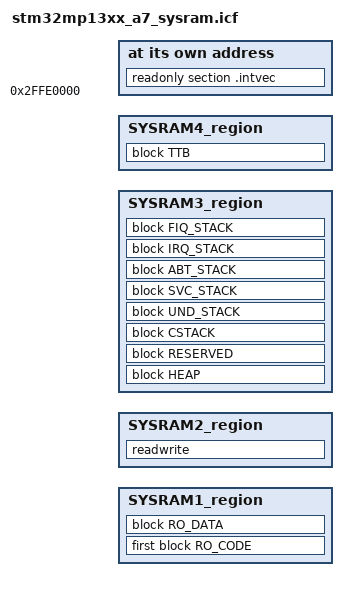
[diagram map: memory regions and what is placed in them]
/*###ICF### Section handled by ICF editor, don't touch! ****/
/*-Editor annotation file-*/
/* IcfEditorFile="$TOOLKIT_DIR$\config\ide\IcfEditor\a_v1_1.xml" */
/*-Specials-*/
define symbol __ICFEDIT_intvec_start__ = 0x2FFE0000;
/*-Memory Regions-*/
define symbol __ICFEDIT_region_SYSRAM1_BASE_start__ = 0x2FFE0000;
define symbol __ICFEDIT_region_SYSRAM1_BASE_end__   = 0x2FFEFFFF;
define symbol __ICFEDIT_region_SYSRAM2_BASE_start__ = 0x2FFF0000;
define symbol __ICFEDIT_region_SYSRAM2_BASE_end__   = 0x2FFF2FFF;
define symbol __ICFEDIT_region_SYSRAM3_BASE_start__ = 0x2FFF3000;
define symbol __ICFEDIT_region_SYSRAM3_BASE_end__   = 0x2FFF7FFF;
define symbol __ICFEDIT_region_SYSRAM4_BASE_start__ = 0x2FFF8000;
define symbol __ICFEDIT_region_SYSRAM4_BASE_end__   = 0x2FFFFFFF;
define symbol __ICFEDIT_region_SRAM1_BASE_start__     = 0x30000000;
define symbol __ICFEDIT_region_SRAM1_BASE_end__        = 0x30003FFF;
define symbol __ICFEDIT_region_SRAM2_BASE_start__      = 0x30004000;
define symbol __ICFEDIT_region_SRAM2_BASE_end__        = 0x30005FFF;
define symbol __ICFEDIT_region_SRAM3_BASE_start__      = 0x30006000;
define symbol __ICFEDIT_region_SRAM3_BASE_end__        = 0x30007FFF;
define symbol __ICFEDIT_region_DDR_BASE_start__  = 0xC0000000;
define symbol __ICFEDIT_region_DDR_BASE_end__    = 0xDF3FFFFF;
/*-Sizes-*/
define symbol __ICFEDIT_size_cstack__   = 0x1000;
define symbol __ICFEDIT_size_svcstack__ = 0x400;
define symbol __ICFEDIT_size_irqstack__ = 0x400;
define symbol __ICFEDIT_size_fiqstack__ = 0x400;
define symbol __ICFEDIT_size_undstack__ = 0x400;
define symbol __ICFEDIT_size_abtstack__ = 0x400;
define symbol __ICFEDIT_size_heap__     = 0x400;
define symbol __ICFEDIT_size_TTB_L1_SIZE__ = 16384;
define symbol __ICFEDIT_size_TTB_L2_SIZE__ = 1024;
define symbol __ICFEDIT_size_RESERVED_SIZE__ = 1024;
/**** End of ICF editor section. ###ICF###*/

define memory mem with size = 4G;
define symbol use_SYSRAM1 = (__ICFEDIT_region_SYSRAM1_BASE_start__ != 0x0 || __ICFEDIT_region_SYSRAM1_BASE_end__ != 0x0);
define symbol use_SYSRAM2 = (__ICFEDIT_region_SYSRAM2_BASE_start__ != 0x0 || __ICFEDIT_region_SYSRAM2_BASE_end__ != 0x0);
define symbol use_SYSRAM3 = (__ICFEDIT_region_SYSRAM3_BASE_start__ != 0x0 || __ICFEDIT_region_SYSRAM3_BASE_end__ != 0x0);
define symbol use_SYSRAM4 = (__ICFEDIT_region_SYSRAM4_BASE_start__ != 0x0 || __ICFEDIT_region_SYSRAM4_BASE_end__ != 0x0);
define symbol use_SRAM1 = (__ICFEDIT_region_SRAM1_BASE_start__ != 0x0 || __ICFEDIT_region_SRAM1_BASE_end__ != 0x0);
define symbol use_SRAM2 = (__ICFEDIT_region_SRAM2_BASE_start__ != 0x0 || __ICFEDIT_region_SRAM2_BASE_end__ != 0x0);
define symbol use_SRAM3 = (__ICFEDIT_region_SRAM3_BASE_start__ != 0x0 || __ICFEDIT_region_SRAM3_BASE_end__ != 0x0);
define symbol use_DDR = (__ICFEDIT_region_DDR_BASE_start__ != 0x0 || __ICFEDIT_region_DDR_BASE_end__ != 0x0);


if (use_SYSRAM1)
{
  define region SYSRAM1_region = mem:[from __ICFEDIT_region_SYSRAM1_BASE_start__ to __ICFEDIT_region_SYSRAM1_BASE_end__];
}
else
{
  define region SYSRAM1_region = [];
}
if (use_SYSRAM2)
{
  define region SYSRAM2_region = mem:[from __ICFEDIT_region_SYSRAM2_BASE_start__ to __ICFEDIT_region_SYSRAM2_BASE_end__];
}
else
{
  define region SYSRAM2_region = [];
}
if (use_SYSRAM3)
{
  define region SYSRAM3_region = mem:[from __ICFEDIT_region_SYSRAM3_BASE_start__ to __ICFEDIT_region_SYSRAM3_BASE_end__];
}
else
{
  define region SYSRAM3_region = [];
}

if (use_SYSRAM4)
{
  define region SYSRAM4_region = mem:[from __ICFEDIT_region_SYSRAM4_BASE_start__ to __ICFEDIT_region_SYSRAM4_BASE_end__];
}
else
{
  define region SYSRAM4_region = [];
}

/* define region SYSRAM_region = SYSRAM1_region | SYSRAM2_region | SYSRAM3_region; */


if (use_DDR)
{
  define region DDR_region = mem:[from __ICFEDIT_region_DDR_BASE_start__ to __ICFEDIT_region_DDR_BASE_end__];
}
else
{
  define region DDR_region = [];
}


initialize by copy { readwrite };
if (isdefinedsymbol(__USE_DLIB_PERTHREAD))
{
  /* Required in a multi-threaded application */
  initialize by copy with packing = none { section __DLIB_PERTHREAD };
}

place at address mem:__ICFEDIT_intvec_start__ { readonly section .intvec };

/*
* RO DATA 4k Alignment done as TTB pages are 4k Aligned. This avoids Prefetch Abort Error.
*/ 
if (!isempty(SYSRAM1_region))
{
  define block RO_CODE { ro code };
  define block RO_DATA with alignment = 4K { ro data };
  place in SYSRAM1_region  { first block RO_CODE, block RO_DATA };
}

if (!isempty(SYSRAM2_region))
{
  place in SYSRAM2_region  { readwrite };
}

/*if (!isempty(EROM_region))
{
  place in EROM_region  { readonly section application_specific_ro };
}
*/

if (!isempty(SYSRAM3_region))
{
  define block HEAP   with alignment = 8, size = __ICFEDIT_size_heap__   { };
  define block RESERVED with alignment = 8, size = __ICFEDIT_size_RESERVED_SIZE__  { };
  define block CSTACK    with alignment = 8, size = __ICFEDIT_size_cstack__   { };
  define block SVC_STACK with alignment = 8, size = __ICFEDIT_size_svcstack__ { };
  define block IRQ_STACK with alignment = 8, size = __ICFEDIT_size_irqstack__ { };
  define block FIQ_STACK with alignment = 8, size = __ICFEDIT_size_fiqstack__ { };
  define block UND_STACK with alignment = 8, size = __ICFEDIT_size_undstack__ { };
  define block ABT_STACK with alignment = 8, size = __ICFEDIT_size_abtstack__ { };
  place in SYSRAM3_region  { block HEAP, block RESERVED,
                          block CSTACK, block UND_STACK,
                          block SVC_STACK, block ABT_STACK,
                          block IRQ_STACK, block FIQ_STACK,};
}

if (!isempty(SYSRAM4_region))
{
  define block TTB    with alignment = 16384, size =  __ICFEDIT_size_TTB_L1_SIZE__ + 4*__ICFEDIT_size_TTB_L2_SIZE__  { };
  place in SYSRAM4_region  {block TTB,};
}

/*
if (!isempty(ERAM_region))
{
  place in ERAM_region  { readwrite section application_specific_rw };
}
*/
